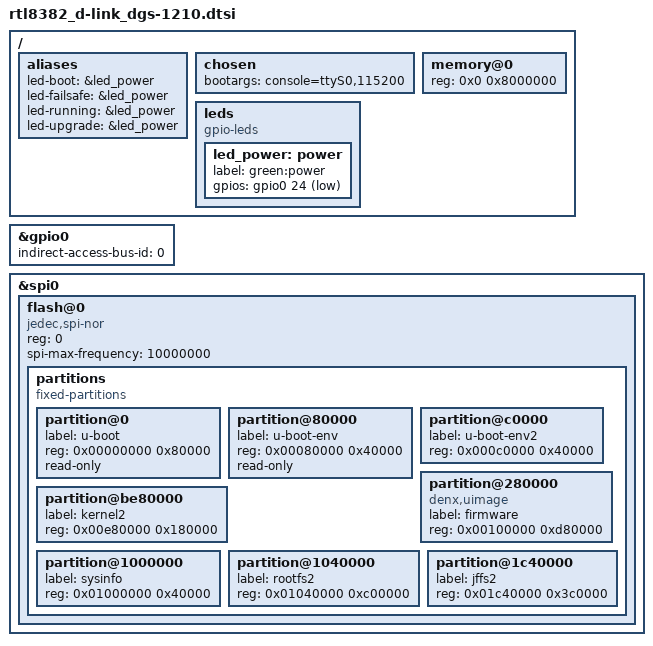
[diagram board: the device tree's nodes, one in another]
// SPDX-License-Identifier: GPL-2.0-or-later OR MIT

#include "rtl838x.dtsi"

#include <dt-bindings/input/input.h>
#include <dt-bindings/gpio/gpio.h>

/ {
	aliases {
		led-boot = &led_power;
		led-failsafe = &led_power;
		led-running = &led_power;
		led-upgrade = &led_power;
	};

	chosen {
		bootargs = "console=ttyS0,115200";
	};

	memory@0 {
		device_type = "memory";
		reg = <0x0 0x8000000>;
	};

	leds {
		compatible = "gpio-leds";

		led_power: power {
			label = "green:power";
			gpios = <&gpio0 24 GPIO_ACTIVE_LOW>;
		};
	};
};

&gpio0 {
	indirect-access-bus-id = <0>;
};

&spi0 {
	status = "okay";
	flash@0 {
		compatible = "jedec,spi-nor";
		reg = <0>;
		spi-max-frequency = <10000000>;

		partitions {
			compatible = "fixed-partitions";
			#address-cells = <1>;
			#size-cells = <1>;

			partition@0 {
				label = "u-boot";
				reg = <0x00000000 0x80000>;
				read-only;
			};
			partition@80000 {
				label = "u-boot-env";
				reg = <0x00080000 0x40000>;
				read-only;
			};
			partition@c0000 {
				label = "u-boot-env2";
				reg = <0x000c0000 0x40000>;
			};
			partition@280000 {
				label = "firmware";
				compatible = "denx,uimage";
				reg = <0x00100000 0xd80000>;
			};
			partition@be80000 {
				label = "kernel2";
				reg = <0x00e80000 0x180000>;
			};
			partition@1000000 {
				label = "sysinfo";
				reg = <0x01000000 0x40000>;
			};
			partition@1040000 {
				label = "rootfs2";
				reg = <0x01040000 0xc00000>;
			};
			partition@1c40000 {
				label = "jffs2";
				reg = <0x01c40000 0x3c0000>;
			};
		};
	};
};
